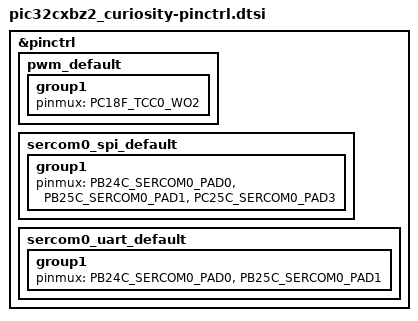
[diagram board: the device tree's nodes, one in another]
/*
 * Copyright (c) 2024 Microchip
 * SPDX-License-Identifier: Apache-2.0
 */

#include <dt-bindings/pinctrl/pic32cx1012bz25048-pinctrl.h>

&pinctrl {
	pwm_default: pwm_default {
		group1 {
			pinmux = <PC18F_TCC0_WO2>;
		};
	};

	sercom0_spi_default: sercom0_spi_default {
		group1 {
			pinmux = <PB24C_SERCOM0_PAD0>,
				 <PB25C_SERCOM0_PAD1>,
				 <PC25C_SERCOM0_PAD3>;
		};
	};

	/*
	sercom0_uart_default: sercom0_uart_default {
		group1 {
			pinmux = <PB12C_SERCOM4_PAD0>,
				 <PB13C_SERCOM4_PAD1>;
		};
	};*/
	
	sercom0_uart_default: sercom0_uart_default {
		group1 {
			pinmux = <PB24C_SERCOM0_PAD0>,
				 <PB25C_SERCOM0_PAD1>;
		};
	};

};
